# STM32L4P5AEI6 register map
File version: 1.0
Registers are 32-bit, access not given, reset 0x0 unless marked. A register's access mark holds for its fields unless they carry their own. Offsets are from the block's base; [hi:lo] are bit positions; {n}, {i} and the like mark numbered series.

## I2C1
Base 0x40005400
Same registers: I2C2 0x40005800, I2C3 0x40005C00, I2C4 0x40008400
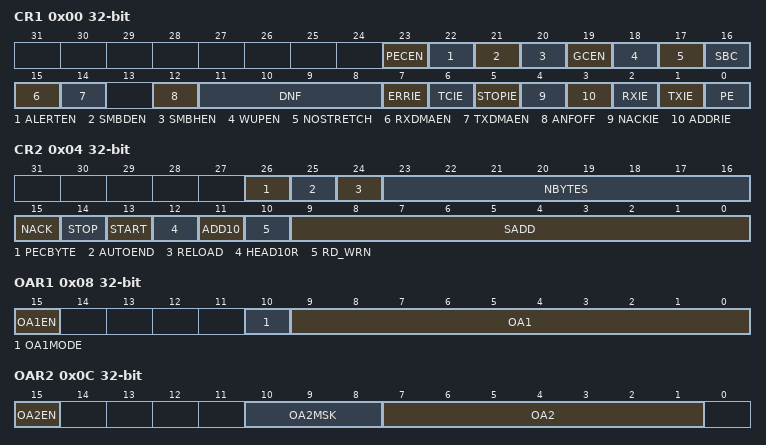
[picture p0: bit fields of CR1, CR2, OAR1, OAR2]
0x00 CR1
  [23] PECEN, [22] ALERTEN, [21] SMBDEN, [20] SMBHEN, [19] GCEN, [18] WUPEN, [17] NOSTRETCH, [16] SBC, [15] RXDMAEN, [14] TXDMAEN, [12] ANFOFF, [11:8] DNF, [7] ERRIE, [6] TCIE, [5] STOPIE, [4] NACKIE, [3] ADDRIE, [2] RXIE, [1] TXIE, [0] PE
0x04 CR2
  [26] PECBYTE, [25] AUTOEND, [24] RELOAD, [23:16] NBYTES, [15] NACK, [14] STOP, [13] START, [12] HEAD10R, [11] ADD10, [10] RD_WRN, [9:0] SADD
0x08 OAR1
  [15] OA1EN, [10] OA1MODE, [9:0] OA1
0x0C OAR2
  [15] OA2EN, [10:8] OA2MSK, [7:1] OA2
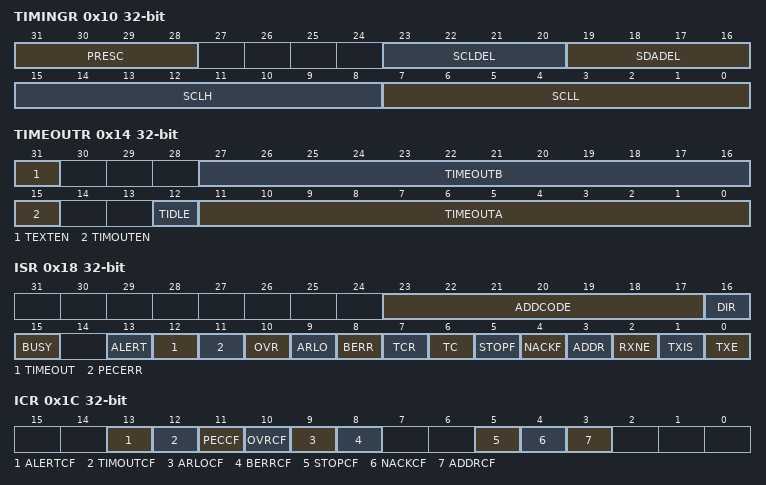
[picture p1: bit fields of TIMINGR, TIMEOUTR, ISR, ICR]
0x10 TIMINGR
  [31:28] PRESC, [23:20] SCLDEL, [19:16] SDADEL, [15:8] SCLH, [7:0] SCLL
0x14 TIMEOUTR
  [31] TEXTEN, [27:16] TIMEOUTB, [15] TIMOUTEN, [12] TIDLE, [11:0] TIMEOUTA
0x18 ISR
  [23:17] ADDCODE, [16] DIR, [15] BUSY, [13] ALERT, [12] TIMEOUT, [11] PECERR, [10] OVR, [9] ARLO, [8] BERR, [7] TCR, [6] TC, [5] STOPF, [4] NACKF, [3] ADDR, [2] RXNE, [1] TXIS, [0] TXE
0x1C ICR
  [13] ALERTCF, [12] TIMOUTCF, [11] PECCF, [10] OVRCF, [9] ARLOCF, [8] BERRCF, [5] STOPCF, [4] NACKCF, [3] ADDRCF
0x20 PECR
  [7:0] PEC
0x24 RXDR
  [7:0] RXDATA
0x28 TXDR
  [7:0] TXDATA

## CRS
Base 0x40006000
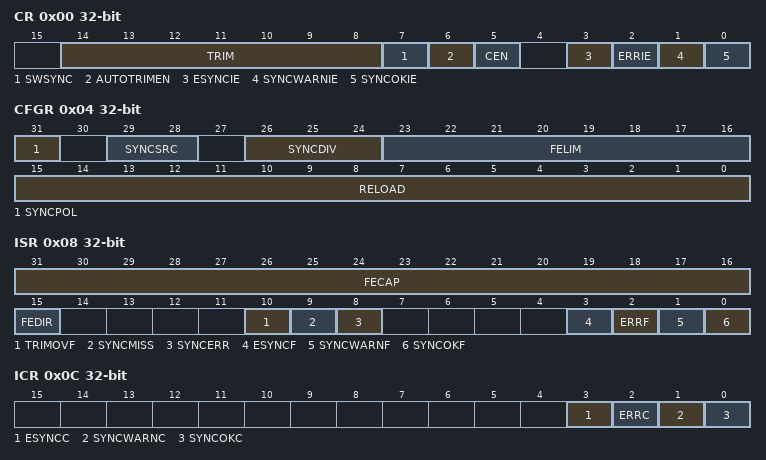
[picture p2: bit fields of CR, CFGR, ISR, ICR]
0x00 CR
  [14:8] TRIM, [7] SWSYNC, [6] AUTOTRIMEN, [5] CEN, [3] ESYNCIE, [2] ERRIE, [1] SYNCWARNIE, [0] SYNCOKIE
0x04 CFGR
  [31] SYNCPOL, [29:28] SYNCSRC, [26:24] SYNCDIV, [23:16] FELIM, [15:0] RELOAD
0x08 ISR
  [31:16] FECAP, [15] FEDIR, [10] TRIMOVF, [9] SYNCMISS, [8] SYNCERR, [3] ESYNCF, [2] ERRF, [1] SYNCWARNF, [0] SYNCOKF
0x0C ICR
  [3] ESYNCC, [2] ERRC, [1] SYNCWARNC, [0] SYNCOKC

## CAN1
Base 0x40006400
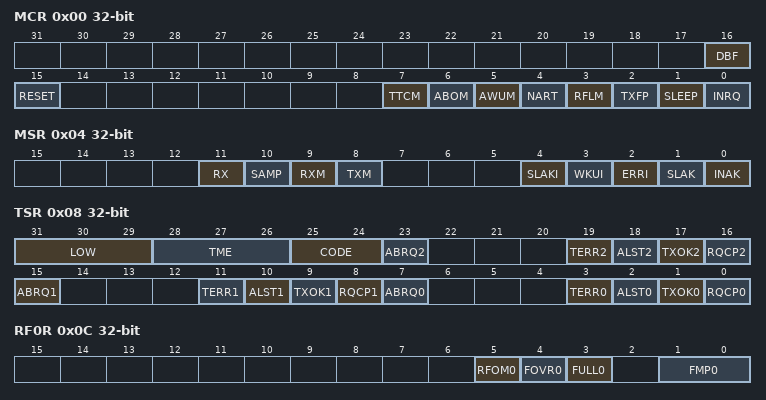
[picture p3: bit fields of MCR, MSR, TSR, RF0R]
0x00 MCR
  [16] DBF, [15] RESET, [7] TTCM, [6] ABOM, [5] AWUM, [4] NART, [3] RFLM, [2] TXFP, [1] SLEEP, [0] INRQ
0x04 MSR
  [11] RX, [10] SAMP, [9] RXM, [8] TXM, [4] SLAKI, [3] WKUI, [2] ERRI, [1] SLAK, [0] INAK
0x08 TSR
  [31:29] LOW, [28:26] TME, [25:24] CODE, [23] ABRQ2, [19] TERR2, [18] ALST2, [17] TXOK2, [16] RQCP2, [15] ABRQ1, [11] TERR1, [10] ALST1, [9] TXOK1, [8] RQCP1, [7] ABRQ0, [3] TERR0, [2] ALST0, [1] TXOK0, [0] RQCP0
0x0C RF0R
  [5] RFOM0, [4] FOVR0, [3] FULL0, [1:0] FMP0
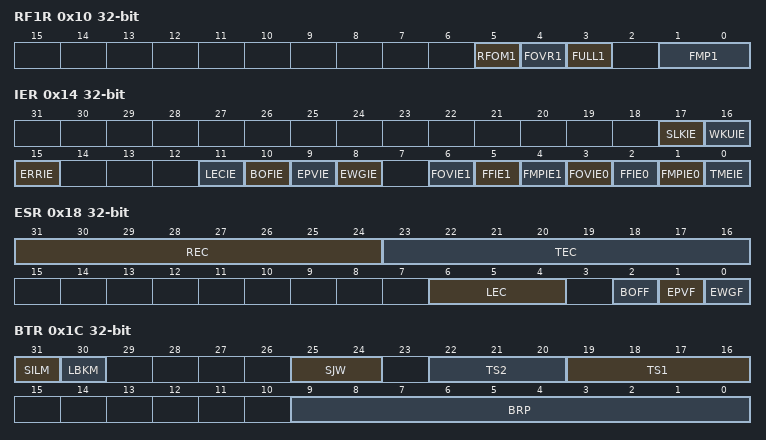
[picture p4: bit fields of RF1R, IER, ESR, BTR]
0x10 RF1R
  [5] RFOM1, [4] FOVR1, [3] FULL1, [1:0] FMP1
0x14 IER
  [17] SLKIE, [16] WKUIE, [15] ERRIE, [11] LECIE, [10] BOFIE, [9] EPVIE, [8] EWGIE, [6] FOVIE1, [5] FFIE1, [4] FMPIE1, [3] FOVIE0, [2] FFIE0, [1] FMPIE0, [0] TMEIE
0x18 ESR
  [31:24] REC, [23:16] TEC, [6:4] LEC, [2] BOFF, [1] EPVF, [0] EWGF
0x1C BTR
  [31] SILM, [30] LBKM, [25:24] SJW, [22:20] TS2, [19:16] TS1, [9:0] BRP
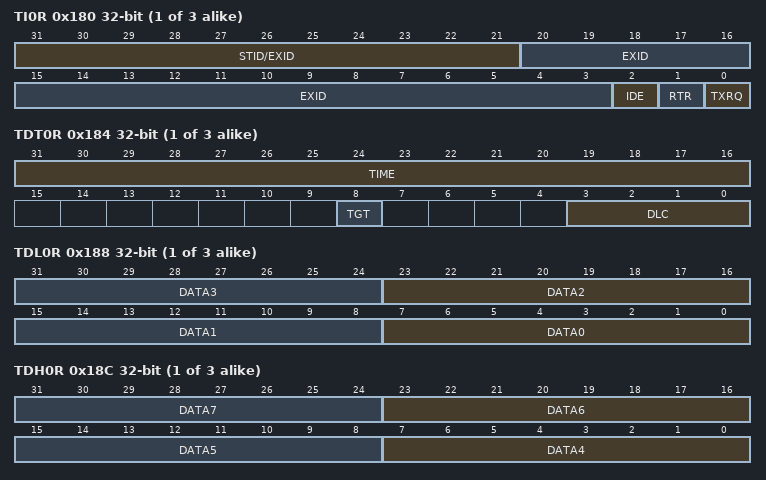
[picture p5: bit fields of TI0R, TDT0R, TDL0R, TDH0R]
{0x180+0x10*i} TI{i}R (i=0..2)
  [31:21] STID/EXID, [20:3] EXID, [2] IDE, [1] RTR, [0] TXRQ
{0x184+0x10*i} TDT{i}R (i=0..2)
  [31:16] TIME, [8] TGT, [3:0] DLC
{0x188+0x10*i} TDL{i}R (i=0..2)
  [8n+7:8n] DATA{n} (n=0..3)
{0x18C+0x10*i} TDH{i}R (i=0..2)
  [8n-25:8n-32] DATA{n} (n=4..7)
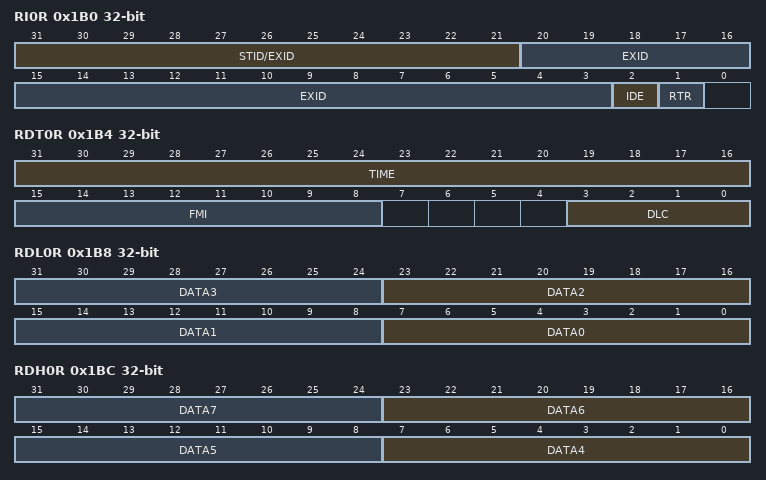
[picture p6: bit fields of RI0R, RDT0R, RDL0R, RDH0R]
0x1B0 RI0R
  [31:21] STID/EXID, [20:3] EXID, [2] IDE, [1] RTR
0x1B4 RDT0R
  [31:16] TIME, [15:8] FMI, [3:0] DLC
0x1B8 RDL0R
  [8n+7:8n] DATA{n} (n=0..3)
0x1BC RDH0R
  [8n-25:8n-32] DATA{n} (n=4..7)
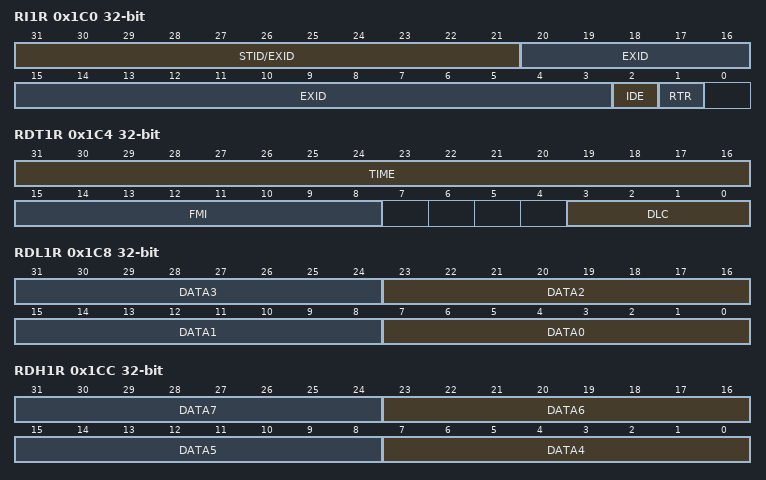
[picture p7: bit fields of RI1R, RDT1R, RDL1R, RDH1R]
0x1C0 RI1R
  [31:21] STID/EXID, [20:3] EXID, [2] IDE, [1] RTR
0x1C4 RDT1R
  [31:16] TIME, [15:8] FMI, [3:0] DLC
0x1C8 RDL1R
  [8n+7:8n] DATA{n} (n=0..3)
0x1CC RDH1R
  [8n-25:8n-32] DATA{n} (n=4..7)
0x20C FS1R
  [27:0] FSC
0x214 FFA1R
  [27:0] FFA
0x21C FA1R
  [27:0] FACT
{0x240+8i} F{i}R1 (i=0..27)
  [31:0] FB
{0x244+8i} F{i}R2 (i=0..27)
  [31:0] FB

## PWR
Base 0x40007000
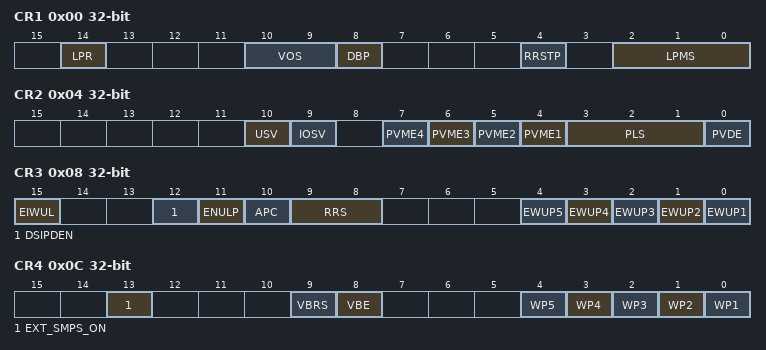
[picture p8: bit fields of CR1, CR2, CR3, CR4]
0x00 CR1
  [14] LPR, [10:9] VOS, [8] DBP, [4] RRSTP, [2:0] LPMS
0x04 CR2
  [10] USV, [9] IOSV, [n+3] PVME{n} (n=1..4), [3:1] PLS, [0] PVDE
0x08 CR3
  [15] EIWUL, [12] DSIPDEN, [11] ENULP, [10] APC, [9:8] RRS, [n-1] EWUP{n} (n=1..5)
0x0C CR4
  [13] EXT_SMPS_ON, [9] VBRS, [8] VBE, [n-1] WP{n} (n=1..5)
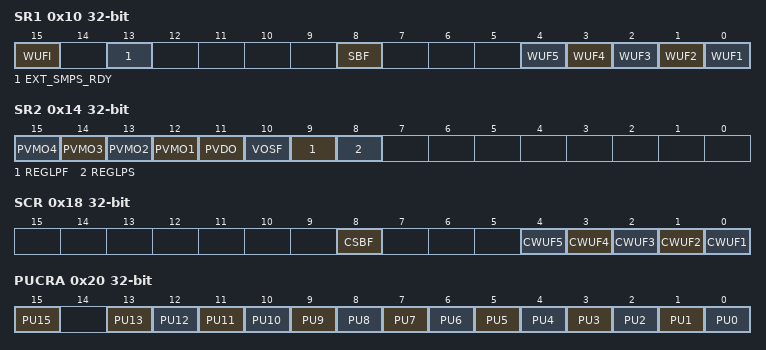
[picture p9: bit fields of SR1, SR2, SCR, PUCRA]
0x10 SR1
  [15] WUFI, [13] EXT_SMPS_RDY, [8] SBF, [n-1] WUF{n} (n=1..5)
0x14 SR2
  [n+11] PVMO{n} (n=1..4), [11] PVDO, [10] VOSF, [9] REGLPF, [8] REGLPS
0x18 SCR
  [8] CSBF, [n-1] CWUF{n} (n=1..5)
0x20 PUCRA
  [15] PU15, [n] PU{n} (n=0..13)
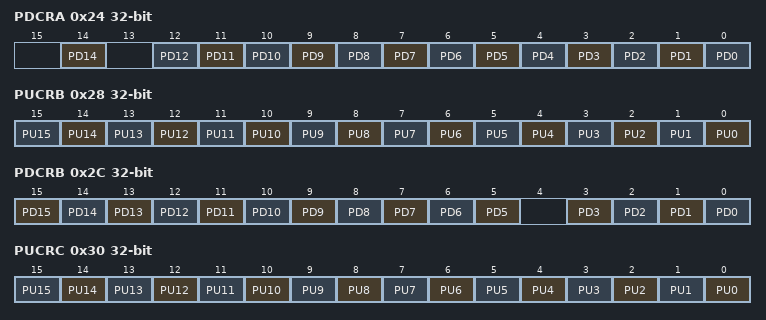
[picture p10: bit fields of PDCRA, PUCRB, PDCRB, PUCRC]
0x24 PDCRA
  [14] PD14, [n] PD{n} (n=0..12)
0x28 PUCRB
  [n] PU{n} (n=0..15)
0x2C PDCRB
  [n] PD{n} (n=5..15), [n] PD{n} (n=0..3)
0x30 PUCRC
  [n] PU{n} (n=0..15)
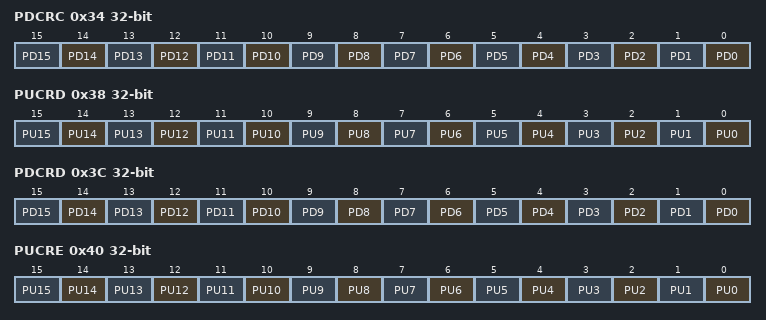
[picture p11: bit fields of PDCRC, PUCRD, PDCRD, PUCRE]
0x34 PDCRC
  [n] PD{n} (n=0..15)
0x38 PUCRD
  [n] PU{n} (n=0..15)
0x3C PDCRD
  [n] PD{n} (n=0..15)
0x40 PUCRE
  [n] PU{n} (n=0..15)
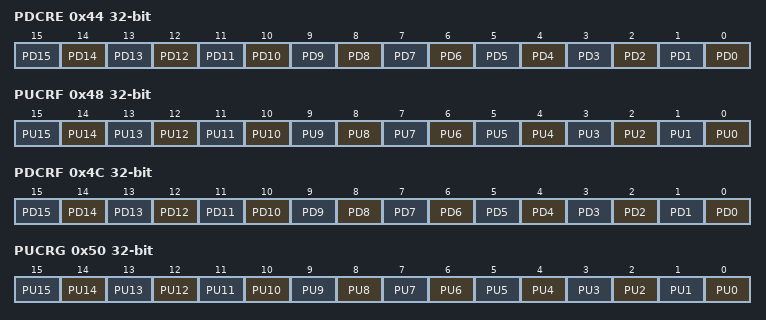
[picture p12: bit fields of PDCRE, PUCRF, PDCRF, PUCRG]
0x44 PDCRE
  [n] PD{n} (n=0..15)
0x48 PUCRF
  [n] PU{n} (n=0..15)
0x4C PDCRF
  [n] PD{n} (n=0..15)
0x50 PUCRG
  [n] PU{n} (n=0..15)
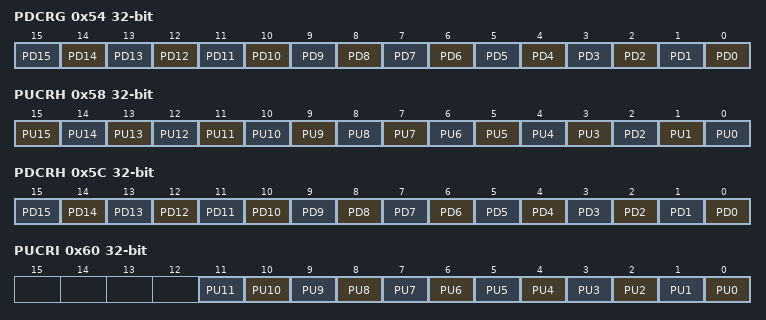
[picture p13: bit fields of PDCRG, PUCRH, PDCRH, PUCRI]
0x54 PDCRG
  [n] PD{n} (n=0..15)
0x58 PUCRH
  [n] PU{n} (n=3..15), [2] PD2, [1] PU1, [0] PU0
0x5C PDCRH
  [n] PD{n} (n=0..15)
0x60 PUCRI
  [n] PU{n} (n=0..11)
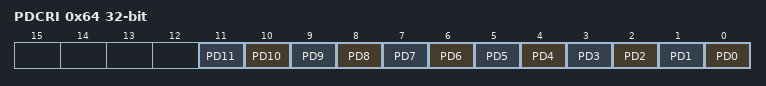
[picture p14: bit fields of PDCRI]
0x64 PDCRI
  [n] PD{n} (n=0..11)
0x80 CR5
  [8] R1MODE
